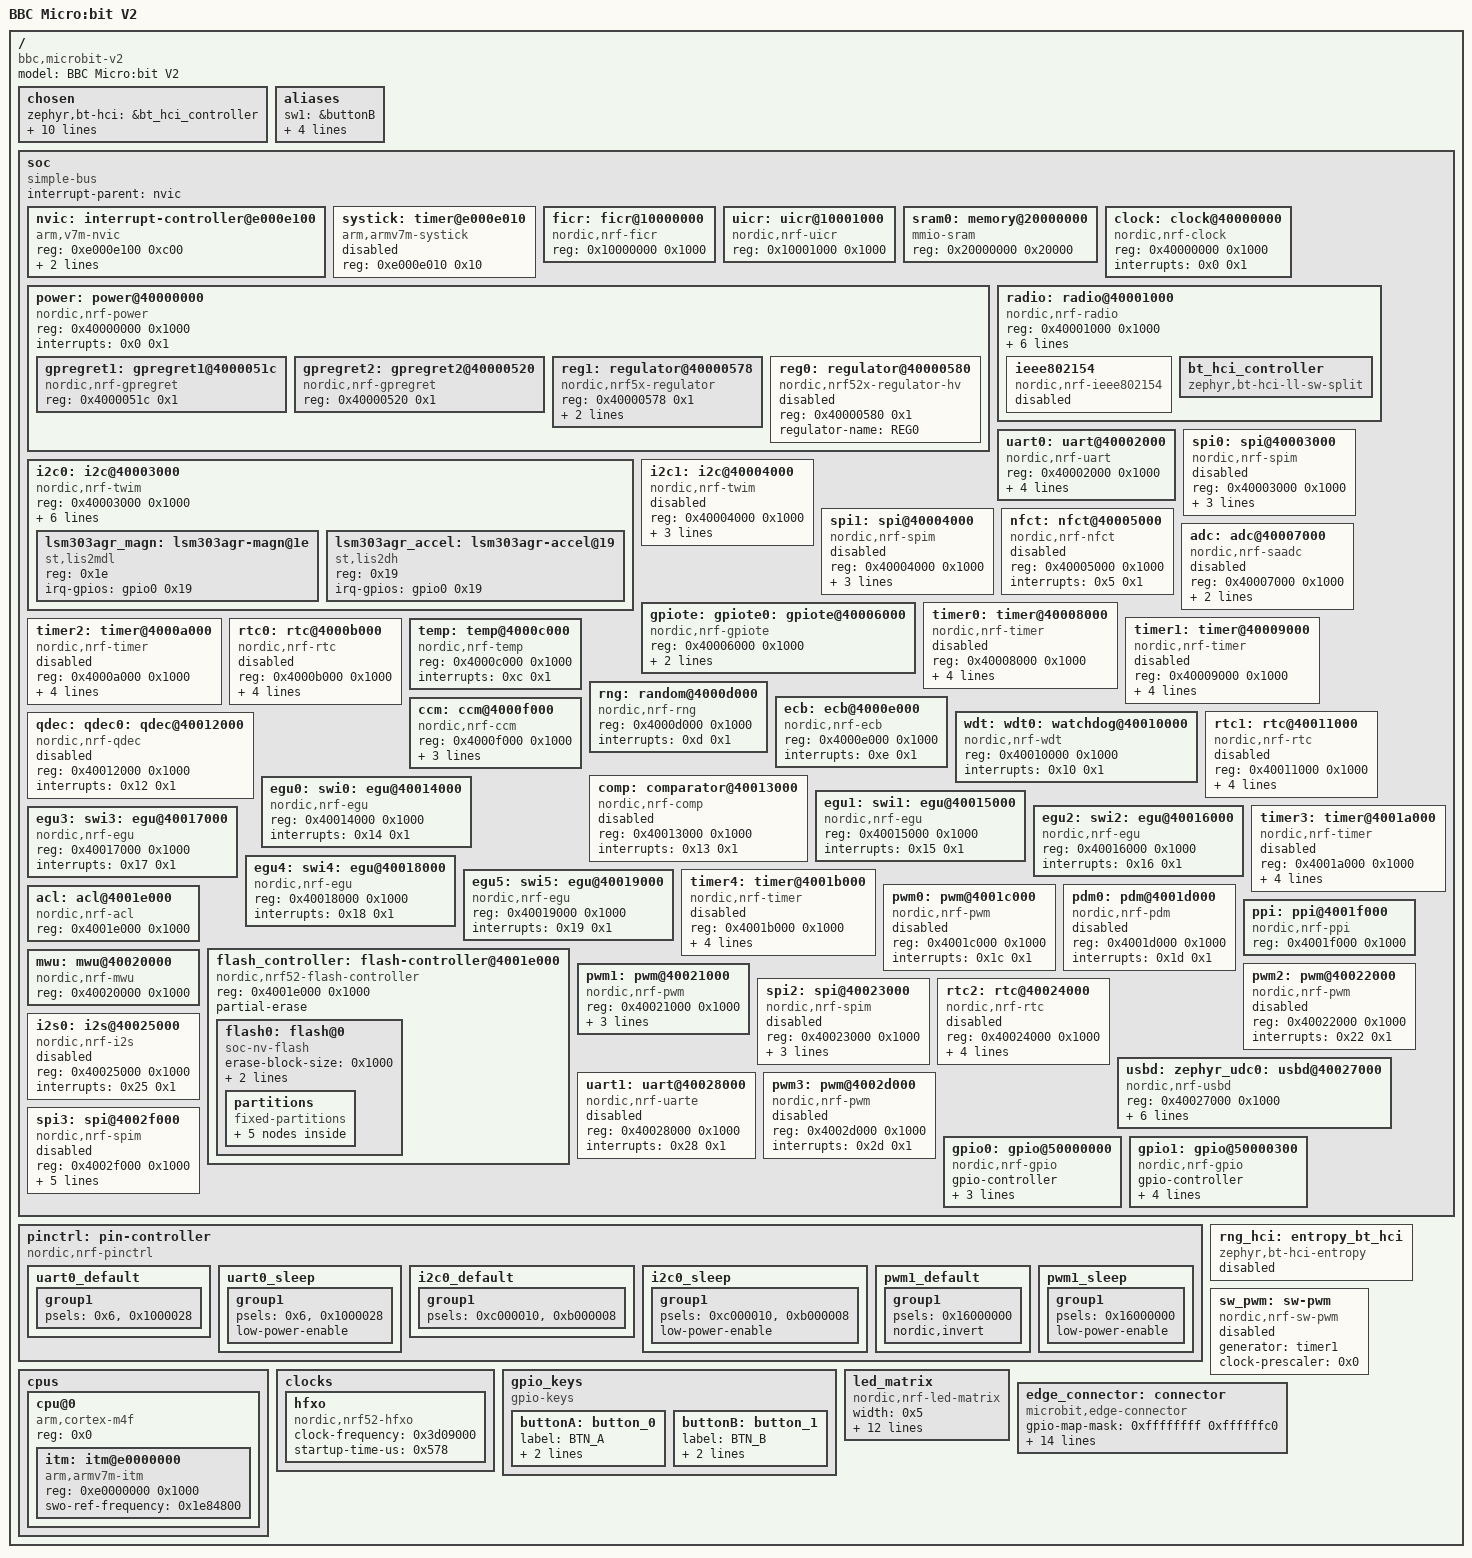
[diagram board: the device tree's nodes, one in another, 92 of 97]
/dts-v1/;

/* node '/' defined in zephyr/dts/common/skeleton.dtsi:9 */
/ {
	#address-cells = < 0x1 >;       /* in zephyr/dts/common/skeleton.dtsi:10 */
	#size-cells = < 0x1 >;          /* in zephyr/dts/common/skeleton.dtsi:11 */
	model = "BBC Micro:bit V2";     /* in zephyr/boards/bbc/microbit_v2/bbc_microbit_v2.dts:13 */
	compatible = "bbc,microbit-v2"; /* in zephyr/boards/bbc/microbit_v2/bbc_microbit_v2.dts:14 */

	/* node '/chosen' defined in zephyr/dts/common/skeleton.dtsi:13 */
	chosen {
		zephyr,bt-hci = &bt_hci_controller;          /* in zephyr/dts/arm/nordic/nrf52833.dtsi:14 */
		zephyr,entropy = &rng;                       /* in zephyr/dts/arm/nordic/nrf52833.dtsi:15 */
		zephyr,flash-controller = &flash_controller; /* in zephyr/dts/arm/nordic/nrf52833.dtsi:16 */
		zephyr,console = &uart0;                     /* in zephyr/boards/bbc/microbit_v2/bbc_microbit_v2.dts:26 */
		zephyr,shell-uart = &uart0;                  /* in zephyr/boards/bbc/microbit_v2/bbc_microbit_v2.dts:27 */
		zephyr,bt-mon-uart = &uart0;                 /* in zephyr/boards/bbc/microbit_v2/bbc_microbit_v2.dts:28 */
		zephyr,bt-c2h-uart = &uart0;                 /* in zephyr/boards/bbc/microbit_v2/bbc_microbit_v2.dts:29 */
		zephyr,sram = &sram0;                        /* in zephyr/boards/bbc/microbit_v2/bbc_microbit_v2.dts:30 */
		zephyr,flash = &flash0;                      /* in zephyr/boards/bbc/microbit_v2/bbc_microbit_v2.dts:31 */
		zephyr,code-partition = &slot0_partition;    /* in zephyr/boards/bbc/microbit_v2/bbc_microbit_v2.dts:32 */
		zephyr,display = &led_matrix;                /* in zephyr/boards/bbc/microbit_v2/bbc_microbit_v2.dts:33 */
	};

	/* node '/aliases' defined in zephyr/dts/common/skeleton.dtsi:15 */
	aliases {
		sw1 = &buttonB;            /* in zephyr/boards/bbc/microbit_v2/bbc_microbit_v2.dts:19 */
		magn0 = &lsm303agr_magn;   /* in zephyr/boards/bbc/microbit_v2/bbc_microbit_v2.dts:20 */
		accel0 = &lsm303agr_accel; /* in zephyr/boards/bbc/microbit_v2/bbc_microbit_v2.dts:21 */
		watchdog0 = &wdt0;         /* in zephyr/boards/bbc/microbit_v2/bbc_microbit_v2.dts:22 */
		sw0 = &buttonA;            /* in example-application/debugging_exercise/boards/bbc_microbit_v2.overlay:10 */
	};

	/* node '/soc' defined in zephyr/dts/arm/armv7-m.dtsi:6 */
	soc {
		#address-cells = < 0x1 >;     /* in zephyr/dts/arm/armv7-m.dtsi:7 */
		#size-cells = < 0x1 >;        /* in zephyr/dts/arm/armv7-m.dtsi:8 */
		interrupt-parent = < &nvic >; /* in zephyr/dts/arm/armv7-m.dtsi:10 */
		ranges;                       /* in zephyr/dts/arm/armv7-m.dtsi:11 */
		compatible = "simple-bus";    /* in zephyr/dts/arm/nordic/nrf52833.dtsi:48 */

		/* node '/soc/interrupt-controller@e000e100' defined in zephyr/dts/arm/armv7-m.dtsi:13 */
		nvic: interrupt-controller@e000e100 {
			#address-cells = < 0x1 >;            /* in zephyr/dts/arm/armv7-m.dtsi:14 */
			compatible = "arm,v7m-nvic";         /* in zephyr/dts/arm/armv7-m.dtsi:15 */
			reg = < 0xe000e100 0xc00 >;          /* in zephyr/dts/arm/armv7-m.dtsi:16 */
			interrupt-controller;                /* in zephyr/dts/arm/armv7-m.dtsi:17 */
			#interrupt-cells = < 0x2 >;          /* in zephyr/dts/arm/armv7-m.dtsi:18 */
			arm,num-irq-priority-bits = < 0x3 >; /* in zephyr/dts/arm/nordic/nrf52833.dtsi:587 */
			phandle = < 0x1 >;                   /* in zephyr/dts/arm/armv7-m.dtsi:10 */
		};

		/* node '/soc/timer@e000e010' defined in zephyr/dts/arm/armv7-m.dtsi:21 */
		systick: timer@e000e010 {
			compatible = "arm,armv7m-systick"; /* in zephyr/dts/arm/armv7-m.dtsi:22 */
			reg = < 0xe000e010 0x10 >;         /* in zephyr/dts/arm/armv7-m.dtsi:23 */
			status = "disabled";               /* in zephyr/dts/arm/nordic/nrf52833.dtsi:592 */
		};

		/* node '/soc/ficr@10000000' defined in zephyr/dts/arm/nordic/nrf52833.dtsi:50 */
		ficr: ficr@10000000 {
			compatible = "nordic,nrf-ficr"; /* in zephyr/dts/arm/nordic/nrf52833.dtsi:51 */
			reg = < 0x10000000 0x1000 >;    /* in zephyr/dts/arm/nordic/nrf52833.dtsi:52 */
			#nordic,ficr-cells = < 0x1 >;   /* in zephyr/dts/arm/nordic/nrf52833.dtsi:53 */
			status = "okay";                /* in zephyr/dts/arm/nordic/nrf52833.dtsi:54 */
		};

		/* node '/soc/uicr@10001000' defined in zephyr/dts/arm/nordic/nrf52833.dtsi:57 */
		uicr: uicr@10001000 {
			compatible = "nordic,nrf-uicr";     /* in zephyr/dts/arm/nordic/nrf52833.dtsi:58 */
			reg = < 0x10001000 0x1000 >;        /* in zephyr/dts/arm/nordic/nrf52833.dtsi:59 */
			ranges = < 0x0 0x10001000 0x1000 >; /* in zephyr/dts/arm/nordic/nrf52833.dtsi:60 */
			status = "okay";                    /* in zephyr/dts/arm/nordic/nrf52833.dtsi:61 */
			#address-cells = < 0x1 >;           /* in zephyr/dts/arm/nordic/nrf52833.dtsi:62 */
			#size-cells = < 0x1 >;              /* in zephyr/dts/arm/nordic/nrf52833.dtsi:63 */
		};

		/* node '/soc/memory@20000000' defined in zephyr/dts/arm/nordic/nrf52833.dtsi:66 */
		sram0: memory@20000000 {
			compatible = "mmio-sram";            /* in zephyr/dts/arm/nordic/nrf52833.dtsi:67 */
			#address-cells = < 0x1 >;            /* in zephyr/dts/arm/nordic/nrf52833.dtsi:68 */
			#size-cells = < 0x1 >;               /* in zephyr/dts/arm/nordic/nrf52833.dtsi:69 */
			reg = < 0x20000000 0x20000 >;        /* in zephyr/dts/arm/nordic/nrf52833_qiaa.dtsi:11 */
			ranges = < 0x0 0x20000000 0x20000 >; /* in zephyr/dts/arm/nordic/nrf52833_qiaa.dtsi:12 */
		};

		/* node '/soc/clock@40000000' defined in zephyr/dts/arm/nordic/nrf52833.dtsi:72 */
		clock: clock@40000000 {
			compatible = "nordic,nrf-clock"; /* in zephyr/dts/arm/nordic/nrf52833.dtsi:73 */
			reg = < 0x40000000 0x1000 >;     /* in zephyr/dts/arm/nordic/nrf52833.dtsi:74 */
			interrupts = < 0x0 0x1 >;        /* in zephyr/dts/arm/nordic/nrf52833.dtsi:75 */
			status = "okay";                 /* in zephyr/dts/arm/nordic/nrf52833.dtsi:76 */
		};

		/* node '/soc/power@40000000' defined in zephyr/dts/arm/nordic/nrf52833.dtsi:79 */
		power: power@40000000 {
			compatible = "nordic,nrf-power"; /* in zephyr/dts/arm/nordic/nrf52833.dtsi:80 */
			reg = < 0x40000000 0x1000 >;     /* in zephyr/dts/arm/nordic/nrf52833.dtsi:81 */
			interrupts = < 0x0 0x1 >;        /* in zephyr/dts/arm/nordic/nrf52833.dtsi:82 */
			status = "okay";                 /* in zephyr/dts/arm/nordic/nrf52833.dtsi:83 */
			#address-cells = < 0x1 >;        /* in zephyr/dts/arm/nordic/nrf52833.dtsi:84 */
			#size-cells = < 0x1 >;           /* in zephyr/dts/arm/nordic/nrf52833.dtsi:85 */

			/* node '/soc/power@40000000/gpregret1@4000051c' defined in zephyr/dts/arm/nordic/nrf52833.dtsi:87 */
			gpregret1: gpregret1@4000051c {
				#address-cells = < 0x1 >;           /* in zephyr/dts/arm/nordic/nrf52833.dtsi:88 */
				#size-cells = < 0x1 >;              /* in zephyr/dts/arm/nordic/nrf52833.dtsi:89 */
				compatible = "nordic,nrf-gpregret"; /* in zephyr/dts/arm/nordic/nrf52833.dtsi:90 */
				reg = < 0x4000051c 0x1 >;           /* in zephyr/dts/arm/nordic/nrf52833.dtsi:91 */
				status = "okay";                    /* in zephyr/dts/arm/nordic/nrf52833.dtsi:92 */
			};

			/* node '/soc/power@40000000/gpregret2@40000520' defined in zephyr/dts/arm/nordic/nrf52833.dtsi:95 */
			gpregret2: gpregret2@40000520 {
				#address-cells = < 0x1 >;           /* in zephyr/dts/arm/nordic/nrf52833.dtsi:96 */
				#size-cells = < 0x1 >;              /* in zephyr/dts/arm/nordic/nrf52833.dtsi:97 */
				compatible = "nordic,nrf-gpregret"; /* in zephyr/dts/arm/nordic/nrf52833.dtsi:98 */
				reg = < 0x40000520 0x1 >;           /* in zephyr/dts/arm/nordic/nrf52833.dtsi:99 */
				status = "okay";                    /* in zephyr/dts/arm/nordic/nrf52833.dtsi:100 */
			};

			/* node '/soc/power@40000000/regulator@40000578' defined in zephyr/dts/arm/nordic/nrf52833.dtsi:103 */
			reg1: regulator@40000578 {
				compatible = "nordic,nrf5x-regulator"; /* in zephyr/dts/arm/nordic/nrf52833.dtsi:104 */
				reg = < 0x40000578 0x1 >;              /* in zephyr/dts/arm/nordic/nrf52833.dtsi:105 */
				regulator-name = "REG1";               /* in zephyr/dts/arm/nordic/nrf52833.dtsi:106 */
				regulator-initial-mode = < 0x0 >;      /* in zephyr/dts/arm/nordic/nrf52833.dtsi:107 */
			};

			/* node '/soc/power@40000000/regulator@40000580' defined in zephyr/dts/arm/nordic/nrf52833.dtsi:110 */
			reg0: regulator@40000580 {
				compatible = "nordic,nrf52x-regulator-hv"; /* in zephyr/dts/arm/nordic/nrf52833.dtsi:111 */
				reg = < 0x40000580 0x1 >;                  /* in zephyr/dts/arm/nordic/nrf52833.dtsi:112 */
				regulator-name = "REG0";                   /* in zephyr/dts/arm/nordic/nrf52833.dtsi:113 */
				status = "disabled";                       /* in zephyr/dts/arm/nordic/nrf52833.dtsi:114 */
			};
		};

		/* node '/soc/radio@40001000' defined in zephyr/dts/arm/nordic/nrf52833.dtsi:118 */
		radio: radio@40001000 {
			compatible = "nordic,nrf-radio"; /* in zephyr/dts/arm/nordic/nrf52833.dtsi:119 */
			reg = < 0x40001000 0x1000 >;     /* in zephyr/dts/arm/nordic/nrf52833.dtsi:120 */
			interrupts = < 0x1 0x1 >;        /* in zephyr/dts/arm/nordic/nrf52833.dtsi:121 */
			status = "okay";                 /* in zephyr/dts/arm/nordic/nrf52833.dtsi:122 */
			dfe-supported;                   /* in zephyr/dts/arm/nordic/nrf52833.dtsi:123 */
			ieee802154-supported;            /* in zephyr/dts/arm/nordic/nrf52833.dtsi:124 */
			ble-2mbps-supported;             /* in zephyr/dts/arm/nordic/nrf52833.dtsi:125 */
			ble-coded-phy-supported;         /* in zephyr/dts/arm/nordic/nrf52833.dtsi:126 */
			radio-tx-high-power-supported;   /* in zephyr/dts/arm/nordic/nrf52833.dtsi:127 */

			/* node '/soc/radio@40001000/ieee802154' defined in zephyr/dts/arm/nordic/nrf52833.dtsi:129 */
			ieee802154: ieee802154 {
				compatible = "nordic,nrf-ieee802154"; /* in zephyr/dts/arm/nordic/nrf52833.dtsi:130 */
				status = "disabled";                  /* in zephyr/dts/arm/nordic/nrf52833.dtsi:131 */
			};

			/* node '/soc/radio@40001000/bt_hci_controller' defined in zephyr/dts/arm/nordic/nrf52833.dtsi:137 */
			bt_hci_controller: bt_hci_controller {
				compatible = "zephyr,bt-hci-ll-sw-split"; /* in zephyr/dts/arm/nordic/nrf52833.dtsi:138 */
				status = "okay";                          /* in zephyr/dts/arm/nordic/nrf52833.dtsi:139 */
			};
		};

		/* node '/soc/uart@40002000' defined in zephyr/dts/arm/nordic/nrf52833.dtsi:143 */
		uart0: uart@40002000 {
			reg = < 0x40002000 0x1000 >;    /* in zephyr/dts/arm/nordic/nrf52833.dtsi:147 */
			interrupts = < 0x2 0x1 >;       /* in zephyr/dts/arm/nordic/nrf52833.dtsi:148 */
			compatible = "nordic,nrf-uart"; /* in zephyr/boards/bbc/microbit_v2/bbc_microbit_v2.dts:126 */
			status = "okay";                /* in zephyr/boards/bbc/microbit_v2/bbc_microbit_v2.dts:127 */
			current-speed = < 0x1c200 >;    /* in zephyr/boards/bbc/microbit_v2/bbc_microbit_v2.dts:128 */
			pinctrl-0 = < &uart0_default >; /* in zephyr/boards/bbc/microbit_v2/bbc_microbit_v2.dts:129 */
			pinctrl-1 = < &uart0_sleep >;   /* in zephyr/boards/bbc/microbit_v2/bbc_microbit_v2.dts:130 */
			pinctrl-names = "default",
			                "sleep";        /* in zephyr/boards/bbc/microbit_v2/bbc_microbit_v2.dts:131 */
		};

		/* node '/soc/i2c@40003000' defined in zephyr/dts/arm/nordic/nrf52833.dtsi:152 */
		i2c0: i2c@40003000 {
			#address-cells = < 0x1 >;       /* in zephyr/dts/arm/nordic/nrf52833.dtsi:161 */
			#size-cells = < 0x0 >;          /* in zephyr/dts/arm/nordic/nrf52833.dtsi:162 */
			reg = < 0x40003000 0x1000 >;    /* in zephyr/dts/arm/nordic/nrf52833.dtsi:163 */
			interrupts = < 0x3 0x1 >;       /* in zephyr/dts/arm/nordic/nrf52833.dtsi:164 */
			easydma-maxcnt-bits = < 0x10 >; /* in zephyr/dts/arm/nordic/nrf52833.dtsi:165 */
			zephyr,pm-device-runtime-auto;  /* in zephyr/dts/arm/nordic/nrf52833.dtsi:167 */
			compatible = "nordic,nrf-twim"; /* in zephyr/boards/bbc/microbit_v2/bbc_microbit_v2.dts:135 */
			status = "okay";                /* in zephyr/boards/bbc/microbit_v2/bbc_microbit_v2.dts:136 */
			clock-frequency = < 0x61a80 >;  /* in zephyr/boards/bbc/microbit_v2/bbc_microbit_v2.dts:137 */
			pinctrl-0 = < &i2c0_default >;  /* in zephyr/boards/bbc/microbit_v2/bbc_microbit_v2.dts:141 */
			pinctrl-1 = < &i2c0_sleep >;    /* in zephyr/boards/bbc/microbit_v2/bbc_microbit_v2.dts:142 */
			pinctrl-names = "default",
			                "sleep";        /* in zephyr/boards/bbc/microbit_v2/bbc_microbit_v2.dts:143 */

			/* node '/soc/i2c@40003000/lsm303agr-magn@1e' defined in zephyr/boards/bbc/microbit_v2/bbc_microbit_v2.dts:145 */
			lsm303agr_magn: lsm303agr-magn@1e {
				compatible = "st,lis2mdl",
				             "st,lsm303agr-magn"; /* in zephyr/boards/bbc/microbit_v2/bbc_microbit_v2.dts:146 */
				status = "okay";                  /* in zephyr/boards/bbc/microbit_v2/bbc_microbit_v2.dts:147 */
				reg = < 0x1e >;                   /* in zephyr/boards/bbc/microbit_v2/bbc_microbit_v2.dts:148 */
				irq-gpios = < &gpio0 0x19 0x0 >;  /* in zephyr/boards/bbc/microbit_v2/bbc_microbit_v2.dts:149 */
			};

			/* node '/soc/i2c@40003000/lsm303agr-accel@19' defined in zephyr/boards/bbc/microbit_v2/bbc_microbit_v2.dts:152 */
			lsm303agr_accel: lsm303agr-accel@19 {
				compatible = "st,lis2dh",
				             "st,lsm303agr-accel"; /* in zephyr/boards/bbc/microbit_v2/bbc_microbit_v2.dts:153 */
				status = "okay";                   /* in zephyr/boards/bbc/microbit_v2/bbc_microbit_v2.dts:154 */
				reg = < 0x19 >;                    /* in zephyr/boards/bbc/microbit_v2/bbc_microbit_v2.dts:155 */
				irq-gpios = < &gpio0 0x19 0x0 >;   /* in zephyr/boards/bbc/microbit_v2/bbc_microbit_v2.dts:156 */
			};
		};

		/* node '/soc/spi@40003000' defined in zephyr/dts/arm/nordic/nrf52833.dtsi:170 */
		spi0: spi@40003000 {
			compatible = "nordic,nrf-spim"; /* in zephyr/dts/arm/nordic/nrf52833.dtsi:178 */
			#address-cells = < 0x1 >;       /* in zephyr/dts/arm/nordic/nrf52833.dtsi:179 */
			#size-cells = < 0x0 >;          /* in zephyr/dts/arm/nordic/nrf52833.dtsi:180 */
			reg = < 0x40003000 0x1000 >;    /* in zephyr/dts/arm/nordic/nrf52833.dtsi:181 */
			interrupts = < 0x3 0x1 >;       /* in zephyr/dts/arm/nordic/nrf52833.dtsi:182 */
			max-frequency = < 0x7a1200 >;   /* in zephyr/dts/arm/nordic/nrf52833.dtsi:183 */
			easydma-maxcnt-bits = < 0x10 >; /* in zephyr/dts/arm/nordic/nrf52833.dtsi:184 */
			status = "disabled";            /* in zephyr/dts/arm/nordic/nrf52833.dtsi:185 */
		};

		/* node '/soc/i2c@40004000' defined in zephyr/dts/arm/nordic/nrf52833.dtsi:188 */
		i2c1: i2c@40004000 {
			compatible = "nordic,nrf-twim"; /* in zephyr/dts/arm/nordic/nrf52833.dtsi:196 */
			#address-cells = < 0x1 >;       /* in zephyr/dts/arm/nordic/nrf52833.dtsi:197 */
			#size-cells = < 0x0 >;          /* in zephyr/dts/arm/nordic/nrf52833.dtsi:198 */
			reg = < 0x40004000 0x1000 >;    /* in zephyr/dts/arm/nordic/nrf52833.dtsi:199 */
			interrupts = < 0x4 0x1 >;       /* in zephyr/dts/arm/nordic/nrf52833.dtsi:200 */
			easydma-maxcnt-bits = < 0x10 >; /* in zephyr/dts/arm/nordic/nrf52833.dtsi:201 */
			status = "disabled";            /* in zephyr/dts/arm/nordic/nrf52833.dtsi:202 */
			zephyr,pm-device-runtime-auto;  /* in zephyr/dts/arm/nordic/nrf52833.dtsi:203 */
		};

		/* node '/soc/spi@40004000' defined in zephyr/dts/arm/nordic/nrf52833.dtsi:206 */
		spi1: spi@40004000 {
			compatible = "nordic,nrf-spim"; /* in zephyr/dts/arm/nordic/nrf52833.dtsi:214 */
			#address-cells = < 0x1 >;       /* in zephyr/dts/arm/nordic/nrf52833.dtsi:215 */
			#size-cells = < 0x0 >;          /* in zephyr/dts/arm/nordic/nrf52833.dtsi:216 */
			reg = < 0x40004000 0x1000 >;    /* in zephyr/dts/arm/nordic/nrf52833.dtsi:217 */
			interrupts = < 0x4 0x1 >;       /* in zephyr/dts/arm/nordic/nrf52833.dtsi:218 */
			max-frequency = < 0x7a1200 >;   /* in zephyr/dts/arm/nordic/nrf52833.dtsi:219 */
			easydma-maxcnt-bits = < 0x10 >; /* in zephyr/dts/arm/nordic/nrf52833.dtsi:220 */
			status = "disabled";            /* in zephyr/dts/arm/nordic/nrf52833.dtsi:221 */
		};

		/* node '/soc/nfct@40005000' defined in zephyr/dts/arm/nordic/nrf52833.dtsi:224 */
		nfct: nfct@40005000 {
			compatible = "nordic,nrf-nfct"; /* in zephyr/dts/arm/nordic/nrf52833.dtsi:225 */
			reg = < 0x40005000 0x1000 >;    /* in zephyr/dts/arm/nordic/nrf52833.dtsi:226 */
			interrupts = < 0x5 0x1 >;       /* in zephyr/dts/arm/nordic/nrf52833.dtsi:227 */
			status = "disabled";            /* in zephyr/dts/arm/nordic/nrf52833.dtsi:228 */
		};

		/* node '/soc/gpiote@40006000' defined in zephyr/dts/arm/nordic/nrf52833.dtsi:231 */
		gpiote: gpiote0: gpiote@40006000 {
			compatible = "nordic,nrf-gpiote"; /* in zephyr/dts/arm/nordic/nrf52833.dtsi:232 */
			reg = < 0x40006000 0x1000 >;      /* in zephyr/dts/arm/nordic/nrf52833.dtsi:233 */
			interrupts = < 0x6 0x5 >;         /* in zephyr/dts/arm/nordic/nrf52833.dtsi:234 */
			instance = < 0x0 >;               /* in zephyr/dts/arm/nordic/nrf52833.dtsi:236 */
			status = "okay";                  /* in zephyr/boards/bbc/microbit_v2/bbc_microbit_v2.dts:106 */
			phandle = < 0x9 >;                /* in zephyr/dts/arm/nordic/nrf52833.dtsi:569 */
		};

		/* node '/soc/adc@40007000' defined in zephyr/dts/arm/nordic/nrf52833.dtsi:239 */
		adc: adc@40007000 {
			compatible = "nordic,nrf-saadc"; /* in zephyr/dts/arm/nordic/nrf52833.dtsi:240 */
			reg = < 0x40007000 0x1000 >;     /* in zephyr/dts/arm/nordic/nrf52833.dtsi:241 */
			interrupts = < 0x7 0x1 >;        /* in zephyr/dts/arm/nordic/nrf52833.dtsi:242 */
			status = "disabled";             /* in zephyr/dts/arm/nordic/nrf52833.dtsi:243 */
			#io-channel-cells = < 0x1 >;     /* in zephyr/dts/arm/nordic/nrf52833.dtsi:244 */
			zephyr,pm-device-runtime-auto;   /* in zephyr/dts/arm/nordic/nrf52833.dtsi:245 */
		};

		/* node '/soc/timer@40008000' defined in zephyr/dts/arm/nordic/nrf52833.dtsi:248 */
		timer0: timer@40008000 {
			compatible = "nordic,nrf-timer"; /* in zephyr/dts/arm/nordic/nrf52833.dtsi:249 */
			status = "disabled";             /* in zephyr/dts/arm/nordic/nrf52833.dtsi:250 */
			reg = < 0x40008000 0x1000 >;     /* in zephyr/dts/arm/nordic/nrf52833.dtsi:251 */
			cc-num = < 0x4 >;                /* in zephyr/dts/arm/nordic/nrf52833.dtsi:252 */
			max-bit-width = < 0x20 >;        /* in zephyr/dts/arm/nordic/nrf52833.dtsi:253 */
			interrupts = < 0x8 0x1 >;        /* in zephyr/dts/arm/nordic/nrf52833.dtsi:254 */
			prescaler = < 0x0 >;             /* in zephyr/dts/arm/nordic/nrf52833.dtsi:255 */
		};

		/* node '/soc/timer@40009000' defined in zephyr/dts/arm/nordic/nrf52833.dtsi:258 */
		timer1: timer@40009000 {
			compatible = "nordic,nrf-timer"; /* in zephyr/dts/arm/nordic/nrf52833.dtsi:259 */
			status = "disabled";             /* in zephyr/dts/arm/nordic/nrf52833.dtsi:260 */
			reg = < 0x40009000 0x1000 >;     /* in zephyr/dts/arm/nordic/nrf52833.dtsi:261 */
			cc-num = < 0x4 >;                /* in zephyr/dts/arm/nordic/nrf52833.dtsi:262 */
			max-bit-width = < 0x20 >;        /* in zephyr/dts/arm/nordic/nrf52833.dtsi:263 */
			interrupts = < 0x9 0x1 >;        /* in zephyr/dts/arm/nordic/nrf52833.dtsi:264 */
			prescaler = < 0x0 >;             /* in zephyr/dts/arm/nordic/nrf52833.dtsi:265 */
			phandle = < 0xa >;               /* in zephyr/dts/vendor/nordic/nrf_common.dtsi:42 */
		};

		/* node '/soc/timer@4000a000' defined in zephyr/dts/arm/nordic/nrf52833.dtsi:268 */
		timer2: timer@4000a000 {
			compatible = "nordic,nrf-timer"; /* in zephyr/dts/arm/nordic/nrf52833.dtsi:269 */
			status = "disabled";             /* in zephyr/dts/arm/nordic/nrf52833.dtsi:270 */
			reg = < 0x4000a000 0x1000 >;     /* in zephyr/dts/arm/nordic/nrf52833.dtsi:271 */
			cc-num = < 0x4 >;                /* in zephyr/dts/arm/nordic/nrf52833.dtsi:272 */
			max-bit-width = < 0x20 >;        /* in zephyr/dts/arm/nordic/nrf52833.dtsi:273 */
			interrupts = < 0xa 0x1 >;        /* in zephyr/dts/arm/nordic/nrf52833.dtsi:274 */
			prescaler = < 0x0 >;             /* in zephyr/dts/arm/nordic/nrf52833.dtsi:275 */
		};

		/* node '/soc/rtc@4000b000' defined in zephyr/dts/arm/nordic/nrf52833.dtsi:278 */
		rtc0: rtc@4000b000 {
			compatible = "nordic,nrf-rtc"; /* in zephyr/dts/arm/nordic/nrf52833.dtsi:279 */
			reg = < 0x4000b000 0x1000 >;   /* in zephyr/dts/arm/nordic/nrf52833.dtsi:280 */
			cc-num = < 0x3 >;              /* in zephyr/dts/arm/nordic/nrf52833.dtsi:281 */
			interrupts = < 0xb 0x1 >;      /* in zephyr/dts/arm/nordic/nrf52833.dtsi:282 */
			status = "disabled";           /* in zephyr/dts/arm/nordic/nrf52833.dtsi:283 */
			clock-frequency = < 0x8000 >;  /* in zephyr/dts/arm/nordic/nrf52833.dtsi:284 */
			prescaler = < 0x1 >;           /* in zephyr/dts/arm/nordic/nrf52833.dtsi:285 */
		};

		/* node '/soc/temp@4000c000' defined in zephyr/dts/arm/nordic/nrf52833.dtsi:288 */
		temp: temp@4000c000 {
			compatible = "nordic,nrf-temp"; /* in zephyr/dts/arm/nordic/nrf52833.dtsi:289 */
			reg = < 0x4000c000 0x1000 >;    /* in zephyr/dts/arm/nordic/nrf52833.dtsi:290 */
			interrupts = < 0xc 0x1 >;       /* in zephyr/dts/arm/nordic/nrf52833.dtsi:291 */
			status = "okay";                /* in zephyr/dts/arm/nordic/nrf52833.dtsi:292 */
		};

		/* node '/soc/random@4000d000' defined in zephyr/dts/arm/nordic/nrf52833.dtsi:295 */
		rng: random@4000d000 {
			compatible = "nordic,nrf-rng"; /* in zephyr/dts/arm/nordic/nrf52833.dtsi:296 */
			reg = < 0x4000d000 0x1000 >;   /* in zephyr/dts/arm/nordic/nrf52833.dtsi:297 */
			interrupts = < 0xd 0x1 >;      /* in zephyr/dts/arm/nordic/nrf52833.dtsi:298 */
			status = "okay";               /* in zephyr/dts/arm/nordic/nrf52833.dtsi:299 */
		};

		/* node '/soc/ecb@4000e000' defined in zephyr/dts/arm/nordic/nrf52833.dtsi:302 */
		ecb: ecb@4000e000 {
			compatible = "nordic,nrf-ecb"; /* in zephyr/dts/arm/nordic/nrf52833.dtsi:303 */
			reg = < 0x4000e000 0x1000 >;   /* in zephyr/dts/arm/nordic/nrf52833.dtsi:304 */
			interrupts = < 0xe 0x1 >;      /* in zephyr/dts/arm/nordic/nrf52833.dtsi:305 */
			status = "okay";               /* in zephyr/dts/arm/nordic/nrf52833.dtsi:306 */
		};

		/* node '/soc/ccm@4000f000' defined in zephyr/dts/arm/nordic/nrf52833.dtsi:309 */
		ccm: ccm@4000f000 {
			compatible = "nordic,nrf-ccm"; /* in zephyr/dts/arm/nordic/nrf52833.dtsi:310 */
			reg = < 0x4000f000 0x1000 >;   /* in zephyr/dts/arm/nordic/nrf52833.dtsi:311 */
			interrupts = < 0xf 0x1 >;      /* in zephyr/dts/arm/nordic/nrf52833.dtsi:312 */
			length-field-length-8-bits;    /* in zephyr/dts/arm/nordic/nrf52833.dtsi:313 */
			headermask-supported;          /* in zephyr/dts/arm/nordic/nrf52833.dtsi:314 */
			status = "okay";               /* in zephyr/dts/arm/nordic/nrf52833.dtsi:315 */
		};

		/* node '/soc/watchdog@40010000' defined in zephyr/dts/arm/nordic/nrf52833.dtsi:318 */
		wdt: wdt0: watchdog@40010000 {
			compatible = "nordic,nrf-wdt"; /* in zephyr/dts/arm/nordic/nrf52833.dtsi:319 */
			reg = < 0x40010000 0x1000 >;   /* in zephyr/dts/arm/nordic/nrf52833.dtsi:320 */
			interrupts = < 0x10 0x1 >;     /* in zephyr/dts/arm/nordic/nrf52833.dtsi:321 */
			status = "okay";               /* in zephyr/dts/arm/nordic/nrf52833.dtsi:322 */
		};

		/* node '/soc/rtc@40011000' defined in zephyr/dts/arm/nordic/nrf52833.dtsi:325 */
		rtc1: rtc@40011000 {
			compatible = "nordic,nrf-rtc"; /* in zephyr/dts/arm/nordic/nrf52833.dtsi:326 */
			reg = < 0x40011000 0x1000 >;   /* in zephyr/dts/arm/nordic/nrf52833.dtsi:327 */
			cc-num = < 0x4 >;              /* in zephyr/dts/arm/nordic/nrf52833.dtsi:328 */
			interrupts = < 0x11 0x1 >;     /* in zephyr/dts/arm/nordic/nrf52833.dtsi:329 */
			status = "disabled";           /* in zephyr/dts/arm/nordic/nrf52833.dtsi:330 */
			clock-frequency = < 0x8000 >;  /* in zephyr/dts/arm/nordic/nrf52833.dtsi:331 */
			prescaler = < 0x1 >;           /* in zephyr/dts/arm/nordic/nrf52833.dtsi:332 */
		};

		/* node '/soc/qdec@40012000' defined in zephyr/dts/arm/nordic/nrf52833.dtsi:335 */
		qdec: qdec0: qdec@40012000 {
			compatible = "nordic,nrf-qdec"; /* in zephyr/dts/arm/nordic/nrf52833.dtsi:336 */
			reg = < 0x40012000 0x1000 >;    /* in zephyr/dts/arm/nordic/nrf52833.dtsi:337 */
			interrupts = < 0x12 0x1 >;      /* in zephyr/dts/arm/nordic/nrf52833.dtsi:338 */
			status = "disabled";            /* in zephyr/dts/arm/nordic/nrf52833.dtsi:339 */
		};

		/* node '/soc/comparator@40013000' defined in zephyr/dts/arm/nordic/nrf52833.dtsi:342 */
		comp: comparator@40013000 {
			compatible = "nordic,nrf-comp"; /* in zephyr/dts/arm/nordic/nrf52833.dtsi:347 */
			reg = < 0x40013000 0x1000 >;    /* in zephyr/dts/arm/nordic/nrf52833.dtsi:348 */
			interrupts = < 0x13 0x1 >;      /* in zephyr/dts/arm/nordic/nrf52833.dtsi:349 */
			status = "disabled";            /* in zephyr/dts/arm/nordic/nrf52833.dtsi:350 */
		};

		/* node '/soc/egu@40014000' defined in zephyr/dts/arm/nordic/nrf52833.dtsi:353 */
		egu0: swi0: egu@40014000 {
			compatible = "nordic,nrf-egu",
			             "nordic,nrf-swi"; /* in zephyr/dts/arm/nordic/nrf52833.dtsi:354 */
			reg = < 0x40014000 0x1000 >;   /* in zephyr/dts/arm/nordic/nrf52833.dtsi:355 */
			interrupts = < 0x14 0x1 >;     /* in zephyr/dts/arm/nordic/nrf52833.dtsi:356 */
			status = "okay";               /* in zephyr/dts/arm/nordic/nrf52833.dtsi:357 */
		};

		/* node '/soc/egu@40015000' defined in zephyr/dts/arm/nordic/nrf52833.dtsi:360 */
		egu1: swi1: egu@40015000 {
			compatible = "nordic,nrf-egu",
			             "nordic,nrf-swi"; /* in zephyr/dts/arm/nordic/nrf52833.dtsi:361 */
			reg = < 0x40015000 0x1000 >;   /* in zephyr/dts/arm/nordic/nrf52833.dtsi:362 */
			interrupts = < 0x15 0x1 >;     /* in zephyr/dts/arm/nordic/nrf52833.dtsi:363 */
			status = "okay";               /* in zephyr/dts/arm/nordic/nrf52833.dtsi:364 */
		};

		/* node '/soc/egu@40016000' defined in zephyr/dts/arm/nordic/nrf52833.dtsi:367 */
		egu2: swi2: egu@40016000 {
			compatible = "nordic,nrf-egu",
			             "nordic,nrf-swi"; /* in zephyr/dts/arm/nordic/nrf52833.dtsi:368 */
			reg = < 0x40016000 0x1000 >;   /* in zephyr/dts/arm/nordic/nrf52833.dtsi:369 */
			interrupts = < 0x16 0x1 >;     /* in zephyr/dts/arm/nordic/nrf52833.dtsi:370 */
			status = "okay";               /* in zephyr/dts/arm/nordic/nrf52833.dtsi:371 */
		};

		/* node '/soc/egu@40017000' defined in zephyr/dts/arm/nordic/nrf52833.dtsi:374 */
		egu3: swi3: egu@40017000 {
			compatible = "nordic,nrf-egu",
			             "nordic,nrf-swi"; /* in zephyr/dts/arm/nordic/nrf52833.dtsi:375 */
			reg = < 0x40017000 0x1000 >;   /* in zephyr/dts/arm/nordic/nrf52833.dtsi:376 */
			interrupts = < 0x17 0x1 >;     /* in zephyr/dts/arm/nordic/nrf52833.dtsi:377 */
			status = "okay";               /* in zephyr/dts/arm/nordic/nrf52833.dtsi:378 */
		};

		/* node '/soc/egu@40018000' defined in zephyr/dts/arm/nordic/nrf52833.dtsi:381 */
		egu4: swi4: egu@40018000 {
			compatible = "nordic,nrf-egu",
			             "nordic,nrf-swi"; /* in zephyr/dts/arm/nordic/nrf52833.dtsi:382 */
			reg = < 0x40018000 0x1000 >;   /* in zephyr/dts/arm/nordic/nrf52833.dtsi:383 */
			interrupts = < 0x18 0x1 >;     /* in zephyr/dts/arm/nordic/nrf52833.dtsi:384 */
			status = "okay";               /* in zephyr/dts/arm/nordic/nrf52833.dtsi:385 */
		};

		/* node '/soc/egu@40019000' defined in zephyr/dts/arm/nordic/nrf52833.dtsi:388 */
		egu5: swi5: egu@40019000 {
			compatible = "nordic,nrf-egu",
			             "nordic,nrf-swi"; /* in zephyr/dts/arm/nordic/nrf52833.dtsi:389 */
			reg = < 0x40019000 0x1000 >;   /* in zephyr/dts/arm/nordic/nrf52833.dtsi:390 */
			interrupts = < 0x19 0x1 >;     /* in zephyr/dts/arm/nordic/nrf52833.dtsi:391 */
			status = "okay";               /* in zephyr/dts/arm/nordic/nrf52833.dtsi:392 */
		};

		/* node '/soc/timer@4001a000' defined in zephyr/dts/arm/nordic/nrf52833.dtsi:395 */
		timer3: timer@4001a000 {
			compatible = "nordic,nrf-timer"; /* in zephyr/dts/arm/nordic/nrf52833.dtsi:396 */
			status = "disabled";             /* in zephyr/dts/arm/nordic/nrf52833.dtsi:397 */
			reg = < 0x4001a000 0x1000 >;     /* in zephyr/dts/arm/nordic/nrf52833.dtsi:398 */
			cc-num = < 0x6 >;                /* in zephyr/dts/arm/nordic/nrf52833.dtsi:399 */
			max-bit-width = < 0x20 >;        /* in zephyr/dts/arm/nordic/nrf52833.dtsi:400 */
			interrupts = < 0x1a 0x1 >;       /* in zephyr/dts/arm/nordic/nrf52833.dtsi:401 */
			prescaler = < 0x0 >;             /* in zephyr/dts/arm/nordic/nrf52833.dtsi:402 */
		};

		/* node '/soc/timer@4001b000' defined in zephyr/dts/arm/nordic/nrf52833.dtsi:405 */
		timer4: timer@4001b000 {
			compatible = "nordic,nrf-timer"; /* in zephyr/dts/arm/nordic/nrf52833.dtsi:406 */
			status = "disabled";             /* in zephyr/dts/arm/nordic/nrf52833.dtsi:407 */
			reg = < 0x4001b000 0x1000 >;     /* in zephyr/dts/arm/nordic/nrf52833.dtsi:408 */
			cc-num = < 0x6 >;                /* in zephyr/dts/arm/nordic/nrf52833.dtsi:409 */
			max-bit-width = < 0x20 >;        /* in zephyr/dts/arm/nordic/nrf52833.dtsi:410 */
			interrupts = < 0x1b 0x1 >;       /* in zephyr/dts/arm/nordic/nrf52833.dtsi:411 */
			prescaler = < 0x0 >;             /* in zephyr/dts/arm/nordic/nrf52833.dtsi:412 */
			phandle = < 0xc >;               /* in zephyr/boards/bbc/microbit_v2/bbc_microbit_v2.dts:73 */
		};

		/* node '/soc/pwm@4001c000' defined in zephyr/dts/arm/nordic/nrf52833.dtsi:415 */
		pwm0: pwm@4001c000 {
			compatible = "nordic,nrf-pwm"; /* in zephyr/dts/arm/nordic/nrf52833.dtsi:416 */
			reg = < 0x4001c000 0x1000 >;   /* in zephyr/dts/arm/nordic/nrf52833.dtsi:417 */
			interrupts = < 0x1c 0x1 >;     /* in zephyr/dts/arm/nordic/nrf52833.dtsi:418 */
			status = "disabled";           /* in zephyr/dts/arm/nordic/nrf52833.dtsi:419 */
			#pwm-cells = < 0x3 >;          /* in zephyr/dts/arm/nordic/nrf52833.dtsi:420 */
			phandle = < 0xd >;             /* in zephyr/boards/bbc/microbit_v2/bbc_microbit_v2.dts:74 */
		};

		/* node '/soc/pdm@4001d000' defined in zephyr/dts/arm/nordic/nrf52833.dtsi:423 */
		pdm0: pdm@4001d000 {
			compatible = "nordic,nrf-pdm"; /* in zephyr/dts/arm/nordic/nrf52833.dtsi:424 */
			reg = < 0x4001d000 0x1000 >;   /* in zephyr/dts/arm/nordic/nrf52833.dtsi:425 */
			interrupts = < 0x1d 0x1 >;     /* in zephyr/dts/arm/nordic/nrf52833.dtsi:426 */
			status = "disabled";           /* in zephyr/dts/arm/nordic/nrf52833.dtsi:427 */
		};

		/* node '/soc/acl@4001e000' defined in zephyr/dts/arm/nordic/nrf52833.dtsi:430 */
		acl: acl@4001e000 {
			compatible = "nordic,nrf-acl"; /* in zephyr/dts/arm/nordic/nrf52833.dtsi:431 */
			reg = < 0x4001e000 0x1000 >;   /* in zephyr/dts/arm/nordic/nrf52833.dtsi:432 */
			status = "okay";               /* in zephyr/dts/arm/nordic/nrf52833.dtsi:433 */
		};

		/* node '/soc/flash-controller@4001e000' defined in zephyr/dts/arm/nordic/nrf52833.dtsi:436 */
		flash_controller: flash-controller@4001e000 {
			compatible = "nordic,nrf52-flash-controller"; /* in zephyr/dts/arm/nordic/nrf52833.dtsi:437 */
			reg = < 0x4001e000 0x1000 >;                  /* in zephyr/dts/arm/nordic/nrf52833.dtsi:438 */
			ranges;                                       /* in zephyr/dts/arm/nordic/nrf52833.dtsi:439 */
			partial-erase;                                /* in zephyr/dts/arm/nordic/nrf52833.dtsi:440 */
			#address-cells = < 0x1 >;                     /* in zephyr/dts/arm/nordic/nrf52833.dtsi:441 */
			#size-cells = < 0x1 >;                        /* in zephyr/dts/arm/nordic/nrf52833.dtsi:442 */

			/* node '/soc/flash-controller@4001e000/flash@0' defined in zephyr/dts/arm/nordic/nrf52833.dtsi:444 */
			flash0: flash@0 {
				compatible = "soc-nv-flash";   /* in zephyr/dts/arm/nordic/nrf52833.dtsi:445 */
				erase-block-size = < 0x1000 >; /* in zephyr/dts/arm/nordic/nrf52833.dtsi:446 */
				write-block-size = < 0x4 >;    /* in zephyr/dts/arm/nordic/nrf52833.dtsi:447 */
				reg = < 0x0 0x80000 >;         /* in zephyr/dts/arm/nordic/nrf52833.dtsi:448 */
				ranges = < 0x0 0x0 0x80000 >;  /* in zephyr/dts/arm/nordic/nrf52833.dtsi:449 */
				status = "okay";               /* in zephyr/dts/arm/nordic/nrf52833.dtsi:450 */
				#address-cells = < 0x1 >;      /* in zephyr/dts/arm/nordic/nrf52833.dtsi:451 */
				#size-cells = < 0x1 >;         /* in zephyr/dts/arm/nordic/nrf52833.dtsi:452 */

				/* node '/soc/flash-controller@4001e000/flash@0/partitions' defined in zephyr/boards/bbc/microbit_v2/bbc_microbit_v2.dts:161 */
				partitions {
					compatible = "fixed-partitions"; /* in zephyr/boards/bbc/microbit_v2/bbc_microbit_v2.dts:162 */
					#address-cells = < 0x1 >;        /* in zephyr/boards/bbc/microbit_v2/bbc_microbit_v2.dts:163 */
					#size-cells = < 0x1 >;           /* in zephyr/boards/bbc/microbit_v2/bbc_microbit_v2.dts:164 */

					/* node '/soc/flash-controller@4001e000/flash@0/partitions/partition@0' defined in zephyr/boards/bbc/microbit_v2/bbc_microbit_v2.dts:166 */
					boot_partition: partition@0 {
						label = "mcuboot";    /* in zephyr/boards/bbc/microbit_v2/bbc_microbit_v2.dts:167 */
						reg = < 0x0 0xc000 >; /* in zephyr/boards/bbc/microbit_v2/bbc_microbit_v2.dts:168 */
					};

					/* node '/soc/flash-controller@4001e000/flash@0/partitions/partition@c000' defined in zephyr/boards/bbc/microbit_v2/bbc_microbit_v2.dts:171 */
					slot0_partition: partition@c000 {
						label = "image-0";        /* in zephyr/boards/bbc/microbit_v2/bbc_microbit_v2.dts:172 */
						reg = < 0xc000 0x32000 >; /* in zephyr/boards/bbc/microbit_v2/bbc_microbit_v2.dts:173 */
					};

					/* node '/soc/flash-controller@4001e000/flash@0/partitions/partition@3e000' defined in zephyr/boards/bbc/microbit_v2/bbc_microbit_v2.dts:176 */
					slot1_partition: partition@3e000 {
						label = "image-1";         /* in zephyr/boards/bbc/microbit_v2/bbc_microbit_v2.dts:177 */
						reg = < 0x3e000 0x32000 >; /* in zephyr/boards/bbc/microbit_v2/bbc_microbit_v2.dts:178 */
					};

					/* node '/soc/flash-controller@4001e000/flash@0/partitions/partition@70000' defined in zephyr/boards/bbc/microbit_v2/bbc_microbit_v2.dts:181 */
					scratch_partition: partition@70000 {
						label = "image-scratch";  /* in zephyr/boards/bbc/microbit_v2/bbc_microbit_v2.dts:182 */
						reg = < 0x70000 0xa000 >; /* in zephyr/boards/bbc/microbit_v2/bbc_microbit_v2.dts:183 */
					};

					/* node '/soc/flash-controller@4001e000/flash@0/partitions/partition@7a000' defined in zephyr/boards/bbc/microbit_v2/bbc_microbit_v2.dts:186 */
					storage_partition: partition@7a000 {
						label = "storage";        /* in zephyr/boards/bbc/microbit_v2/bbc_microbit_v2.dts:187 */
						reg = < 0x7a000 0x6000 >; /* in zephyr/boards/bbc/microbit_v2/bbc_microbit_v2.dts:188 */
					};
				};
			};
		};

		/* node '/soc/ppi@4001f000' defined in zephyr/dts/arm/nordic/nrf52833.dtsi:456 */
		ppi: ppi@4001f000 {
			compatible = "nordic,nrf-ppi"; /* in zephyr/dts/arm/nordic/nrf52833.dtsi:457 */
			reg = < 0x4001f000 0x1000 >;   /* in zephyr/dts/arm/nordic/nrf52833.dtsi:458 */
			status = "okay";               /* in zephyr/dts/arm/nordic/nrf52833.dtsi:459 */
		};

		/* node '/soc/mwu@40020000' defined in zephyr/dts/arm/nordic/nrf52833.dtsi:462 */
		mwu: mwu@40020000 {
			compatible = "nordic,nrf-mwu"; /* in zephyr/dts/arm/nordic/nrf52833.dtsi:463 */
			reg = < 0x40020000 0x1000 >;   /* in zephyr/dts/arm/nordic/nrf52833.dtsi:464 */
			status = "okay";               /* in zephyr/dts/arm/nordic/nrf52833.dtsi:465 */
		};

		/* node '/soc/pwm@40021000' defined in zephyr/dts/arm/nordic/nrf52833.dtsi:468 */
		pwm1: pwm@40021000 {
			compatible = "nordic,nrf-pwm"; /* in zephyr/dts/arm/nordic/nrf52833.dtsi:469 */
			reg = < 0x40021000 0x1000 >;   /* in zephyr/dts/arm/nordic/nrf52833.dtsi:470 */
			interrupts = < 0x21 0x1 >;     /* in zephyr/dts/arm/nordic/nrf52833.dtsi:471 */
			#pwm-cells = < 0x3 >;          /* in zephyr/dts/arm/nordic/nrf52833.dtsi:473 */
			status = "okay";               /* in zephyr/boards/bbc/microbit_v2/bbc_microbit_v2.dts:119 */
			pinctrl-0 = < &pwm1_default >; /* in zephyr/boards/bbc/microbit_v2/bbc_microbit_v2.dts:120 */
			pinctrl-1 = < &pwm1_sleep >;   /* in zephyr/boards/bbc/microbit_v2/bbc_microbit_v2.dts:121 */
			pinctrl-names = "default",
			                "sleep";       /* in zephyr/boards/bbc/microbit_v2/bbc_microbit_v2.dts:122 */
		};

		/* node '/soc/pwm@40022000' defined in zephyr/dts/arm/nordic/nrf52833.dtsi:476 */
		pwm2: pwm@40022000 {
			compatible = "nordic,nrf-pwm"; /* in zephyr/dts/arm/nordic/nrf52833.dtsi:477 */
			reg = < 0x40022000 0x1000 >;   /* in zephyr/dts/arm/nordic/nrf52833.dtsi:478 */
			interrupts = < 0x22 0x1 >;     /* in zephyr/dts/arm/nordic/nrf52833.dtsi:479 */
			status = "disabled";           /* in zephyr/dts/arm/nordic/nrf52833.dtsi:480 */
			#pwm-cells = < 0x3 >;          /* in zephyr/dts/arm/nordic/nrf52833.dtsi:481 */
		};

		/* node '/soc/spi@40023000' defined in zephyr/dts/arm/nordic/nrf52833.dtsi:484 */
		spi2: spi@40023000 {
			compatible = "nordic,nrf-spim"; /* in zephyr/dts/arm/nordic/nrf52833.dtsi:492 */
			#address-cells = < 0x1 >;       /* in zephyr/dts/arm/nordic/nrf52833.dtsi:493 */
			#size-cells = < 0x0 >;          /* in zephyr/dts/arm/nordic/nrf52833.dtsi:494 */
			reg = < 0x40023000 0x1000 >;    /* in zephyr/dts/arm/nordic/nrf52833.dtsi:495 */
			interrupts = < 0x23 0x1 >;      /* in zephyr/dts/arm/nordic/nrf52833.dtsi:496 */
			max-frequency = < 0x7a1200 >;   /* in zephyr/dts/arm/nordic/nrf52833.dtsi:497 */
			easydma-maxcnt-bits = < 0x10 >; /* in zephyr/dts/arm/nordic/nrf52833.dtsi:498 */
			status = "disabled";            /* in zephyr/dts/arm/nordic/nrf52833.dtsi:499 */
		};

		/* node '/soc/rtc@40024000' defined in zephyr/dts/arm/nordic/nrf52833.dtsi:502 */
		rtc2: rtc@40024000 {
			compatible = "nordic,nrf-rtc"; /* in zephyr/dts/arm/nordic/nrf52833.dtsi:503 */
			reg = < 0x40024000 0x1000 >;   /* in zephyr/dts/arm/nordic/nrf52833.dtsi:504 */
			cc-num = < 0x4 >;              /* in zephyr/dts/arm/nordic/nrf52833.dtsi:505 */
			interrupts = < 0x24 0x1 >;     /* in zephyr/dts/arm/nordic/nrf52833.dtsi:506 */
			status = "disabled";           /* in zephyr/dts/arm/nordic/nrf52833.dtsi:507 */
			clock-frequency = < 0x8000 >;  /* in zephyr/dts/arm/nordic/nrf52833.dtsi:508 */
			prescaler = < 0x1 >;           /* in zephyr/dts/arm/nordic/nrf52833.dtsi:509 */
		};

		/* node '/soc/i2s@40025000' defined in zephyr/dts/arm/nordic/nrf52833.dtsi:512 */
		i2s0: i2s@40025000 {
			compatible = "nordic,nrf-i2s"; /* in zephyr/dts/arm/nordic/nrf52833.dtsi:513 */
			#address-cells = < 0x1 >;      /* in zephyr/dts/arm/nordic/nrf52833.dtsi:514 */
			#size-cells = < 0x0 >;         /* in zephyr/dts/arm/nordic/nrf52833.dtsi:515 */
			reg = < 0x40025000 0x1000 >;   /* in zephyr/dts/arm/nordic/nrf52833.dtsi:516 */
			interrupts = < 0x25 0x1 >;     /* in zephyr/dts/arm/nordic/nrf52833.dtsi:517 */
			status = "disabled";           /* in zephyr/dts/arm/nordic/nrf52833.dtsi:518 */
		};

		/* node '/soc/usbd@40027000' defined in zephyr/dts/arm/nordic/nrf52833.dtsi:521 */
		usbd: zephyr_udc0: usbd@40027000 {
			reg = < 0x40027000 0x1000 >;    /* in zephyr/dts/arm/nordic/nrf52833.dtsi:523 */
			interrupts = < 0x27 0x1 >;      /* in zephyr/dts/arm/nordic/nrf52833.dtsi:524 */
			num-bidir-endpoints = < 0x1 >;  /* in zephyr/dts/arm/nordic/nrf52833.dtsi:525 */
			num-in-endpoints = < 0x7 >;     /* in zephyr/dts/arm/nordic/nrf52833.dtsi:526 */
			num-out-endpoints = < 0x7 >;    /* in zephyr/dts/arm/nordic/nrf52833.dtsi:527 */
			num-isoin-endpoints = < 0x1 >;  /* in zephyr/dts/arm/nordic/nrf52833.dtsi:528 */
			num-isoout-endpoints = < 0x1 >; /* in zephyr/dts/arm/nordic/nrf52833.dtsi:529 */
			compatible = "nordic,nrf-usbd"; /* in zephyr/boards/bbc/microbit_v2/bbc_microbit_v2.dts:194 */
			status = "okay";                /* in zephyr/boards/bbc/microbit_v2/bbc_microbit_v2.dts:195 */
		};

		/* node '/soc/uart@40028000' defined in zephyr/dts/arm/nordic/nrf52833.dtsi:533 */
		uart1: uart@40028000 {
			compatible = "nordic,nrf-uarte"; /* in zephyr/dts/arm/nordic/nrf52833.dtsi:534 */
			reg = < 0x40028000 0x1000 >;     /* in zephyr/dts/arm/nordic/nrf52833.dtsi:535 */
			interrupts = < 0x28 0x1 >;       /* in zephyr/dts/arm/nordic/nrf52833.dtsi:536 */
			status = "disabled";             /* in zephyr/dts/arm/nordic/nrf52833.dtsi:537 */
		};

		/* node '/soc/pwm@4002d000' defined in zephyr/dts/arm/nordic/nrf52833.dtsi:540 */
		pwm3: pwm@4002d000 {
			compatible = "nordic,nrf-pwm"; /* in zephyr/dts/arm/nordic/nrf52833.dtsi:541 */
			reg = < 0x4002d000 0x1000 >;   /* in zephyr/dts/arm/nordic/nrf52833.dtsi:542 */
			interrupts = < 0x2d 0x1 >;     /* in zephyr/dts/arm/nordic/nrf52833.dtsi:543 */
			status = "disabled";           /* in zephyr/dts/arm/nordic/nrf52833.dtsi:544 */
			#pwm-cells = < 0x3 >;          /* in zephyr/dts/arm/nordic/nrf52833.dtsi:545 */
		};

		/* node '/soc/spi@4002f000' defined in zephyr/dts/arm/nordic/nrf52833.dtsi:548 */
		spi3: spi@4002f000 {
			compatible = "nordic,nrf-spim"; /* in zephyr/dts/arm/nordic/nrf52833.dtsi:549 */
			#address-cells = < 0x1 >;       /* in zephyr/dts/arm/nordic/nrf52833.dtsi:550 */
			#size-cells = < 0x0 >;          /* in zephyr/dts/arm/nordic/nrf52833.dtsi:551 */
			reg = < 0x4002f000 0x1000 >;    /* in zephyr/dts/arm/nordic/nrf52833.dtsi:552 */
			interrupts = < 0x2f 0x1 >;      /* in zephyr/dts/arm/nordic/nrf52833.dtsi:553 */
			max-frequency = < 0x1e84800 >;  /* in zephyr/dts/arm/nordic/nrf52833.dtsi:554 */
			easydma-maxcnt-bits = < 0x10 >; /* in zephyr/dts/arm/nordic/nrf52833.dtsi:555 */
			rx-delay-supported;             /* in zephyr/dts/arm/nordic/nrf52833.dtsi:556 */
			rx-delay = < 0x2 >;             /* in zephyr/dts/arm/nordic/nrf52833.dtsi:557 */
			status = "disabled";            /* in zephyr/dts/arm/nordic/nrf52833.dtsi:558 */
		};

		/* node '/soc/gpio@50000000' defined in zephyr/dts/arm/nordic/nrf52833.dtsi:561 */
		gpio0: gpio@50000000 {
			compatible = "nordic,nrf-gpio";              /* in zephyr/dts/arm/nordic/nrf52833.dtsi:562 */
			gpio-controller;                             /* in zephyr/dts/arm/nordic/nrf52833.dtsi:563 */
			reg = < 0x50000000 0x200 0x50000500 0x300 >; /* in zephyr/dts/arm/nordic/nrf52833.dtsi:564 */
			#gpio-cells = < 0x2 >;                       /* in zephyr/dts/arm/nordic/nrf52833.dtsi:566 */
			port = < 0x0 >;                              /* in zephyr/dts/arm/nordic/nrf52833.dtsi:568 */
			gpiote-instance = < &gpiote >;               /* in zephyr/dts/arm/nordic/nrf52833.dtsi:569 */
			status = "okay";                             /* in example-application/debugging_exercise/boards/bbc_microbit_v2.overlay:15 */
			phandle = < 0x6 >;                           /* in zephyr/boards/bbc/microbit_v2/bbc_microbit_v2.dts:149 */
		};

		/* node '/soc/gpio@50000300' defined in zephyr/dts/arm/nordic/nrf52833.dtsi:572 */
		gpio1: gpio@50000300 {
			compatible = "nordic,nrf-gpio";              /* in zephyr/dts/arm/nordic/nrf52833.dtsi:573 */
			gpio-controller;                             /* in zephyr/dts/arm/nordic/nrf52833.dtsi:574 */
			reg = < 0x50000300 0x200 0x50000800 0x300 >; /* in zephyr/dts/arm/nordic/nrf52833.dtsi:575 */
			#gpio-cells = < 0x2 >;                       /* in zephyr/dts/arm/nordic/nrf52833.dtsi:577 */
			ngpios = < 0xa >;                            /* in zephyr/dts/arm/nordic/nrf52833.dtsi:578 */
			port = < 0x1 >;                              /* in zephyr/dts/arm/nordic/nrf52833.dtsi:580 */
			gpiote-instance = < &gpiote >;               /* in zephyr/dts/arm/nordic/nrf52833.dtsi:581 */
			status = "okay";                             /* in zephyr/boards/bbc/microbit_v2/bbc_microbit_v2.dts:114 */
			phandle = < 0xb >;                           /* in zephyr/boards/bbc/microbit_v2/bbc_microbit_v2.dts:67 */
		};
	};

	/* node '/pin-controller' defined in zephyr/dts/vendor/nordic/nrf_common.dtsi:26 */
	pinctrl: pin-controller {
		compatible = "nordic,nrf-pinctrl"; /* in zephyr/dts/vendor/nordic/nrf_common.dtsi:31 */

		/* node '/pin-controller/uart0_default' defined in zephyr/boards/bbc/microbit_v2/bbc_microbit_v2-pinctrl.dtsi:7 */
		uart0_default: uart0_default {
			phandle = < 0x2 >; /* in zephyr/boards/bbc/microbit_v2/bbc_microbit_v2.dts:129 */

			/* node '/pin-controller/uart0_default/group1' defined in zephyr/boards/bbc/microbit_v2/bbc_microbit_v2-pinctrl.dtsi:8 */
			group1 {
				psels = < 0x6 >,
				        < 0x1000028 >; /* in zephyr/boards/bbc/microbit_v2/bbc_microbit_v2-pinctrl.dtsi:9 */
			};
		};

		/* node '/pin-controller/uart0_sleep' defined in zephyr/boards/bbc/microbit_v2/bbc_microbit_v2-pinctrl.dtsi:14 */
		uart0_sleep: uart0_sleep {
			phandle = < 0x3 >; /* in zephyr/boards/bbc/microbit_v2/bbc_microbit_v2.dts:130 */

			/* node '/pin-controller/uart0_sleep/group1' defined in zephyr/boards/bbc/microbit_v2/bbc_microbit_v2-pinctrl.dtsi:15 */
			group1 {
				psels = < 0x6 >,
				        < 0x1000028 >; /* in zephyr/boards/bbc/microbit_v2/bbc_microbit_v2-pinctrl.dtsi:16 */
				low-power-enable;      /* in zephyr/boards/bbc/microbit_v2/bbc_microbit_v2-pinctrl.dtsi:18 */
			};
		};

		/* node '/pin-controller/i2c0_default' defined in zephyr/boards/bbc/microbit_v2/bbc_microbit_v2-pinctrl.dtsi:22 */
		i2c0_default: i2c0_default {
			phandle = < 0x4 >; /* in zephyr/boards/bbc/microbit_v2/bbc_microbit_v2.dts:141 */

			/* node '/pin-controller/i2c0_default/group1' defined in zephyr/boards/bbc/microbit_v2/bbc_microbit_v2-pinctrl.dtsi:23 */
			group1 {
				psels = < 0xc000010 >,
				        < 0xb000008 >; /* in zephyr/boards/bbc/microbit_v2/bbc_microbit_v2-pinctrl.dtsi:24 */
			};
		};

		/* node '/pin-controller/i2c0_sleep' defined in zephyr/boards/bbc/microbit_v2/bbc_microbit_v2-pinctrl.dtsi:29 */
		i2c0_sleep: i2c0_sleep {
			phandle = < 0x5 >; /* in zephyr/boards/bbc/microbit_v2/bbc_microbit_v2.dts:142 */

			/* node '/pin-controller/i2c0_sleep/group1' defined in zephyr/boards/bbc/microbit_v2/bbc_microbit_v2-pinctrl.dtsi:30 */
			group1 {
				psels = < 0xc000010 >,
				        < 0xb000008 >; /* in zephyr/boards/bbc/microbit_v2/bbc_microbit_v2-pinctrl.dtsi:31 */
				low-power-enable;      /* in zephyr/boards/bbc/microbit_v2/bbc_microbit_v2-pinctrl.dtsi:33 */
			};
		};

		/* node '/pin-controller/pwm1_default' defined in zephyr/boards/bbc/microbit_v2/bbc_microbit_v2-pinctrl.dtsi:37 */
		pwm1_default: pwm1_default {
			phandle = < 0x7 >; /* in zephyr/boards/bbc/microbit_v2/bbc_microbit_v2.dts:120 */

			/* node '/pin-controller/pwm1_default/group1' defined in zephyr/boards/bbc/microbit_v2/bbc_microbit_v2-pinctrl.dtsi:38 */
			group1 {
				psels = < 0x16000000 >; /* in zephyr/boards/bbc/microbit_v2/bbc_microbit_v2-pinctrl.dtsi:39 */
				nordic,invert;          /* in zephyr/boards/bbc/microbit_v2/bbc_microbit_v2-pinctrl.dtsi:40 */
			};
		};

		/* node '/pin-controller/pwm1_sleep' defined in zephyr/boards/bbc/microbit_v2/bbc_microbit_v2-pinctrl.dtsi:44 */
		pwm1_sleep: pwm1_sleep {
			phandle = < 0x8 >; /* in zephyr/boards/bbc/microbit_v2/bbc_microbit_v2.dts:121 */

			/* node '/pin-controller/pwm1_sleep/group1' defined in zephyr/boards/bbc/microbit_v2/bbc_microbit_v2-pinctrl.dtsi:45 */
			group1 {
				psels = < 0x16000000 >; /* in zephyr/boards/bbc/microbit_v2/bbc_microbit_v2-pinctrl.dtsi:46 */
				low-power-enable;       /* in zephyr/boards/bbc/microbit_v2/bbc_microbit_v2-pinctrl.dtsi:47 */
			};
		};
	};

	/* node '/entropy_bt_hci' defined in zephyr/dts/vendor/nordic/nrf_common.dtsi:34 */
	rng_hci: entropy_bt_hci {
		compatible = "zephyr,bt-hci-entropy"; /* in zephyr/dts/vendor/nordic/nrf_common.dtsi:35 */
		status = "disabled";                  /* in zephyr/dts/vendor/nordic/nrf_common.dtsi:36 */
	};

	/* node '/sw-pwm' defined in zephyr/dts/vendor/nordic/nrf_common.dtsi:39 */
	sw_pwm: sw-pwm {
		compatible = "nordic,nrf-sw-pwm"; /* in zephyr/dts/vendor/nordic/nrf_common.dtsi:40 */
		status = "disabled";              /* in zephyr/dts/vendor/nordic/nrf_common.dtsi:41 */
		generator = < &timer1 >;          /* in zephyr/dts/vendor/nordic/nrf_common.dtsi:42 */
		clock-prescaler = < 0x0 >;        /* in zephyr/dts/vendor/nordic/nrf_common.dtsi:43 */
		#pwm-cells = < 0x3 >;             /* in zephyr/dts/vendor/nordic/nrf_common.dtsi:44 */
	};

	/* node '/cpus' defined in zephyr/dts/arm/nordic/nrf52833.dtsi:19 */
	cpus {
		#address-cells = < 0x1 >; /* in zephyr/dts/arm/nordic/nrf52833.dtsi:20 */
		#size-cells = < 0x0 >;    /* in zephyr/dts/arm/nordic/nrf52833.dtsi:21 */

		/* node '/cpus/cpu@0' defined in zephyr/dts/arm/nordic/nrf52833.dtsi:23 */
		cpu@0 {
			device_type = "cpu";           /* in zephyr/dts/arm/nordic/nrf52833.dtsi:24 */
			compatible = "arm,cortex-m4f"; /* in zephyr/dts/arm/nordic/nrf52833.dtsi:25 */
			reg = < 0x0 >;                 /* in zephyr/dts/arm/nordic/nrf52833.dtsi:26 */
			#address-cells = < 0x1 >;      /* in zephyr/dts/arm/nordic/nrf52833.dtsi:27 */
			#size-cells = < 0x1 >;         /* in zephyr/dts/arm/nordic/nrf52833.dtsi:28 */

			/* node '/cpus/cpu@0/itm@e0000000' defined in zephyr/dts/arm/nordic/nrf52833.dtsi:30 */
			itm: itm@e0000000 {
				compatible = "arm,armv7m-itm";     /* in zephyr/dts/arm/nordic/nrf52833.dtsi:31 */
				reg = < 0xe0000000 0x1000 >;       /* in zephyr/dts/arm/nordic/nrf52833.dtsi:32 */
				swo-ref-frequency = < 0x1e84800 >; /* in zephyr/dts/arm/nordic/nrf52833.dtsi:33 */
			};
		};
	};

	/* node '/clocks' defined in zephyr/dts/arm/nordic/nrf52833.dtsi:38 */
	clocks {

		/* node '/clocks/hfxo' defined in zephyr/dts/arm/nordic/nrf52833.dtsi:39 */
		hfxo: hfxo {
			compatible = "nordic,nrf52-hfxo"; /* in zephyr/dts/arm/nordic/nrf52833.dtsi:40 */
			clock-frequency = < 0x3d09000 >;  /* in zephyr/dts/arm/nordic/nrf52833.dtsi:41 */
			startup-time-us = < 0x578 >;      /* in zephyr/dts/arm/nordic/nrf52833.dtsi:42 */
			#clock-cells = < 0x0 >;           /* in zephyr/dts/arm/nordic/nrf52833.dtsi:43 */
		};
	};

	/* node '/gpio_keys' defined in zephyr/boards/bbc/microbit_v2/bbc_microbit_v2.dts:36 */
	gpio_keys {
		compatible = "gpio-keys"; /* in zephyr/boards/bbc/microbit_v2/bbc_microbit_v2.dts:37 */

		/* node '/gpio_keys/button_0' defined in zephyr/boards/bbc/microbit_v2/bbc_microbit_v2.dts:39 */
		buttonA: button_0 {
			label = "BTN_A";            /* in zephyr/boards/bbc/microbit_v2/bbc_microbit_v2.dts:40 */
			gpios = < &gpio0 0xe 0x1 >; /* in zephyr/boards/bbc/microbit_v2/bbc_microbit_v2.dts:41 */
			zephyr,code = < 0x1e >;     /* in zephyr/boards/bbc/microbit_v2/bbc_microbit_v2.dts:42 */
		};

		/* node '/gpio_keys/button_1' defined in zephyr/boards/bbc/microbit_v2/bbc_microbit_v2.dts:45 */
		buttonB: button_1 {
			label = "BTN_B";             /* in zephyr/boards/bbc/microbit_v2/bbc_microbit_v2.dts:46 */
			gpios = < &gpio0 0x17 0x1 >; /* in zephyr/boards/bbc/microbit_v2/bbc_microbit_v2.dts:47 */
			zephyr,code = < 0x30 >;      /* in zephyr/boards/bbc/microbit_v2/bbc_microbit_v2.dts:48 */
		};
	};

	/* node '/led_matrix' defined in zephyr/boards/bbc/microbit_v2/bbc_microbit_v2.dts:52 */
	led_matrix: led_matrix {
		compatible = "nordic,nrf-led-matrix";                                                           /* in zephyr/boards/bbc/microbit_v2/bbc_microbit_v2.dts:53 */
		status = "okay";                                                                                /* in zephyr/boards/bbc/microbit_v2/bbc_microbit_v2.dts:54 */
		width = < 0x5 >;                                                                                /* in zephyr/boards/bbc/microbit_v2/bbc_microbit_v2.dts:55 */
		height = < 0x5 >;                                                                               /* in zephyr/boards/bbc/microbit_v2/bbc_microbit_v2.dts:56 */
		pixel-mapping = [ 00 01 02 03 04 10 11 12 13 14 20 21 22 23 24 30 31 32 33 34 40 41 42 43 44 ]; /* in zephyr/boards/bbc/microbit_v2/bbc_microbit_v2.dts:57 */
		row-gpios = < &gpio0 0x15 0x0 >,
		            < &gpio0 0x16 0x0 >,
		            < &gpio0 0xf 0x0 >,
		            < &gpio0 0x18 0x0 >,
		            < &gpio0 0x13 0x0 >;                                                                /* in zephyr/boards/bbc/microbit_v2/bbc_microbit_v2.dts:62 */
		col-gpios = < &gpio0 0x1c 0x1 >,
		            < &gpio0 0xb 0x1 >,
		            < &gpio0 0x1f 0x1 >,
		            < &gpio1 0x5 0x1 >,
		            < &gpio0 0x1e 0x1 >;                                                                /* in zephyr/boards/bbc/microbit_v2/bbc_microbit_v2.dts:67 */
		refresh-frequency = < 0x32 >;                                                                   /* in zephyr/boards/bbc/microbit_v2/bbc_microbit_v2.dts:72 */
		timer = < &timer4 >;                                                                            /* in zephyr/boards/bbc/microbit_v2/bbc_microbit_v2.dts:73 */
		pwm = < &pwm0 >;                                                                                /* in zephyr/boards/bbc/microbit_v2/bbc_microbit_v2.dts:74 */
		pixel-group-size = < 0x4 >;                                                                     /* in zephyr/boards/bbc/microbit_v2/bbc_microbit_v2.dts:75 */
	};

	/* node '/connector' defined in zephyr/boards/bbc/microbit_v2/bbc_microbit_v2.dts:78 */
	edge_connector: connector {
		compatible = "microbit,edge-connector";    /* in zephyr/boards/bbc/microbit_v2/bbc_microbit_v2.dts:79 */
		#gpio-cells = < 0x2 >;                     /* in zephyr/boards/bbc/microbit_v2/bbc_microbit_v2.dts:80 */
		gpio-map-mask = < 0xffffffff 0xffffffc0 >; /* in zephyr/boards/bbc/microbit_v2/bbc_microbit_v2.dts:81 */
		gpio-map-pass-thru = < 0x0 0x3f >;         /* in zephyr/boards/bbc/microbit_v2/bbc_microbit_v2.dts:82 */
		gpio-map = < 0x0 0x0 &gpio0 0x2 0x0 >,
		           < 0x1 0x0 &gpio0 0x3 0x0 >,
		           < 0x2 0x0 &gpio0 0x4 0x0 >,
		           < 0x3 0x0 &gpio0 0x1f 0x0 >,
		           < 0x4 0x0 &gpio0 0x1c 0x0 >,
		           < 0x5 0x0 &gpio0 0xe 0x0 >,
		           < 0x6 0x0 &gpio1 0x5 0x0 >,
		           < 0x7 0x0 &gpio0 0xb 0x0 >,
		           < 0x8 0x0 &gpio0 0xa 0x0 >,
		           < 0x9 0x0 &gpio0 0x9 0x0 >,
		           < 0xa 0x0 &gpio0 0x1e 0x0 >,
		           < 0xb 0x0 &gpio0 0x17 0x0 >,
		           < 0xc 0x0 &gpio0 0xc 0x0 >,
		           < 0xd 0x0 &gpio0 0x11 0x0 >,
		           < 0xe 0x0 &gpio0 0x1 0x0 >,
		           < 0xf 0x0 &gpio0 0xd 0x0 >,
		           < 0x10 0x0 &gpio1 0x2 0x0 >,
		           < 0x13 0x0 &gpio0 0x1a 0x0 >,
		           < 0x14 0x0 &gpio1 0x0 0x0 >;    /* in zephyr/boards/bbc/microbit_v2/bbc_microbit_v2.dts:83 */
	};
};
